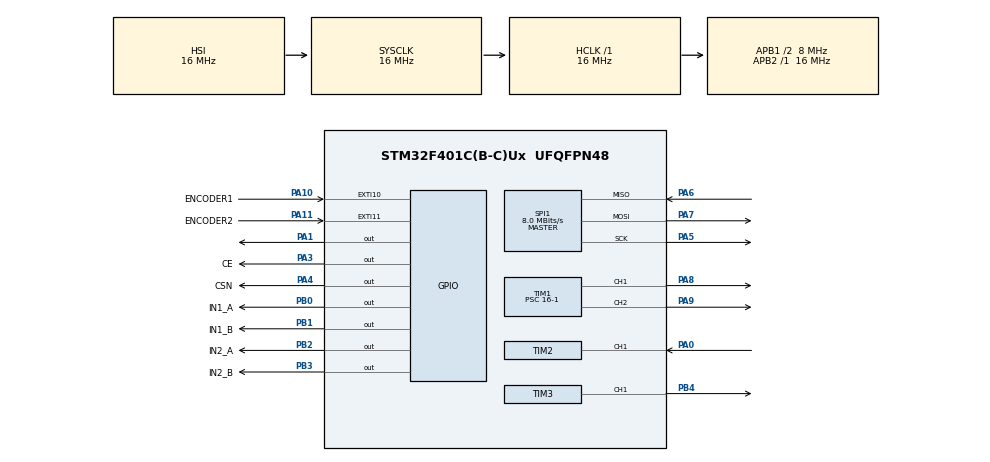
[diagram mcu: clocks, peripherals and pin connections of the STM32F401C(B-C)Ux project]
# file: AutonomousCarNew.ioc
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Mcu.Family=STM32F4
Mcu.Name=STM32F401C(B-C)Ux
Mcu.Package=UFQFPN48
NVIC.EXTI15_10_IRQn=true\:0\:0\:false\:false\:true\:true\:true\:true
NVIC.PriorityGroup=NVIC_PRIORITYGROUP_4
NVIC.TIM2_IRQn=true\:0\:0\:false\:false\:true\:true\:true\:true
PA0-WKUP.Signal=S_TIM2_CH1_ETR
PA1.Signal=GPIO_Output
PA10.GPIO_Label=ENCODER1
PA10.GPIO_PuPd=GPIO_PULLUP
PA10.Signal=GPXTI10
PA11.GPIO_Label=ENCODER2
PA11.GPIO_PuPd=GPIO_PULLUP
PA11.Signal=GPXTI11
PA13.Mode=Serial_Wire
PA13.Signal=SYS_JTMS-SWDIO
PA14.Mode=Serial_Wire
PA14.Signal=SYS_JTCK-SWCLK
PA3.GPIO_Label=CE
PA3.Signal=GPIO_Output
PA4.GPIO_Label=CSN
PA4.Signal=GPIO_Output
PA5.Mode=Full_Duplex_Master
PA5.Signal=SPI1_SCK
PA6.Mode=Full_Duplex_Master
PA6.Signal=SPI1_MISO
PA7.Mode=Full_Duplex_Master
PA7.Signal=SPI1_MOSI
PA8.Signal=S_TIM1_CH1
PA9.Signal=S_TIM1_CH2
PB0.GPIO_Label=IN1_A
PB0.Signal=GPIO_Output
PB1.GPIO_Label=IN1_B
PB1.Signal=GPIO_Output
PB2.GPIO_Label=IN2_A
PB2.Signal=GPIO_Output
PB3.GPIO_Label=IN2_B
PB3.Signal=GPIO_Output
PB4.Signal=S_TIM3_CH1
PH0\ -\ OSC_IN.Mode=HSE-External-Oscillator
PH0\ -\ OSC_IN.Signal=RCC_OSC_IN
PH1\ -\ OSC_OUT.Mode=HSE-External-Oscillator
PH1\ -\ OSC_OUT.Signal=RCC_OSC_OUT
ProjectManager.HeapSize=0x200
ProjectManager.StackSize=0x400
ProjectManager.TargetToolchain=MDK-ARM V5.32
RCC.48MHZClocksFreq_Value=42000000
RCC.AHBFreq_Value=16000000
RCC.APB1CLKDivider=RCC_HCLK_DIV2
RCC.APB1Freq_Value=8000000
RCC.APB1TimFreq_Value=16000000
RCC.APB2Freq_Value=16000000
RCC.APB2TimFreq_Value=16000000
RCC.CortexFreq_Value=16000000
RCC.HCLKFreq_Value=16000000
RCC.HSE_VALUE=25000000
RCC.HSI_VALUE=16000000
RCC.LSE_VALUE=32768
RCC.PLLM=8
RCC.PLLN=84
RCC.SYSCLKFreq_VALUE=16000000
RCC.VCOOutputFreq_Value=168000000
SH.S_TIM1_CH1.0=TIM1_CH1,PWM Generation1 CH1
SH.S_TIM1_CH2.0=TIM1_CH2,PWM Generation2 CH2
SH.S_TIM2_CH1_ETR.0=TIM2_CH1,Input_Capture1_from_TI1
SH.S_TIM3_CH1.0=TIM3_CH1,PWM Generation1 CH1
SPI1.BaudRatePrescaler=SPI_BAUDRATEPRESCALER_2
SPI1.CalculateBaudRate=8.0 MBits/s
SPI1.Direction=SPI_DIRECTION_2LINES
SPI1.Mode=SPI_MODE_MASTER
SPI1.VirtualType=VM_MASTER
TIM1.Channel-PWM\ Generation1\ CH1=TIM_CHANNEL_1
TIM1.Channel-PWM\ Generation2\ CH2=TIM_CHANNEL_2
TIM1.Period=2000
TIM1.Prescaler=16-1
TIM1.Pulse-PWM\ Generation1\ CH1=500
TIM1.Pulse-PWM\ Generation2\ CH2=500
TIM2.Channel-Input_Capture1_from_TI1=TIM_CHANNEL_1
TIM2.Period=0xffffffff
TIM2.Prescaler=16-1
TIM3.Channel-PWM\ Generation1\ CH1=TIM_CHANNEL_1
TIM3.Period=20000
TIM3.Prescaler=16-1
TIM3.Pulse-PWM\ Generation1\ CH1=2000
VP_TIM1_VS_ClockSourceINT.Mode=Internal
VP_TIM2_VS_ClockSourceINT.Mode=Internal
VP_TIM3_VS_ClockSourceINT.Mode=Internal
board=custom

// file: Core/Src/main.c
/* USER CODE BEGIN Header */
/**
  ******************************************************************************
  * @file           : main.c
  * @brief          : Main program body
  ******************************************************************************
  * @attention
  *
  * Copyright (c) 2023 STMicroelectronics.
  * All rights reserved.
  *
  * This software is licensed under terms that can be found in the LICENSE file
  * in the root directory of this software component.
  * If no LICENSE file comes with this software, it is provided AS-IS.
  *
  ******************************************************************************
  */
/* USER CODE END Header */
#include "main.h"

/* USER CODE BEGIN Includes */
#include "NRF24L01.h"
#include "HC_SR04.h"
/* USER CODE END Includes */

/* USER CODE BEGIN PD */
#define MAX_LENGTH_DATA 32
/* USER CODE END PD */

SPI_HandleTypeDef hspi1;

TIM_HandleTypeDef htim1;
TIM_HandleTypeDef htim2;
TIM_HandleTypeDef htim3;

/* USER CODE BEGIN PV */
extern uint8_t Distance;

uint8_t LimitDistance = 20, ReadingSensorAvailable = 1; // 5cm

uint32_t Count1 = 0, Count2 = 0;

uint16_t value;

uint8_t RX_Address[] = {0xEE, 0xDD, 0xCC, 0xBB, 0xAA};

uint8_t RX_Data[MAX_LENGTH_DATA];

typedef struct ReceivedValue
{
	char command1;
	char command2;
	uint16_t data;
} RECEIVED_VALUE;

typedef struct Direction
{
	uint8_t left;
	uint8_t right;
	uint8_t up;
	uint8_t back;
} DIRECTION;

RECEIVED_VALUE DataPackage;

DIRECTION DirectionValue;

void (*ModeFunction) ();

// =============================== FOR PID VARIABLE =================================
//double T, Pulse, Speed, ConstitutionSpeed, E, E1, E2, Alpha, Beta, Gamma, Kp, Kd, Ki, Output, LastOutPut;
double T;

typedef struct PIDType
{
	double Pulse, Speed, ConstitutionSpeed, E, E1, E2, Alpha, Beta, Gamma, Kp, Kd, Ki, Output, LastOutPut;
} PID_TYPE;

PID_TYPE Motor1;
PID_TYPE Motor2;

/* USER CODE END PV */

void SystemClock_Config(void);
static void MX_GPIO_Init(void);
static void MX_SPI1_Init(void);
static void MX_TIM1_Init(void);
static void MX_TIM2_Init(void);
static void MX_TIM3_Init(void);

/* USER CODE BEGIN 0 */
// =========================== FOR PID ALGORITHM =================================

void SetUpPID(PID_TYPE *motor, double cSpeed)
{
	motor->ConstitutionSpeed = cSpeed; // constitution speed in RPM
	//Speed = 0;
	motor->E = motor->E1 = motor->E2 = 0;
	//motor->Output  0;
	motor->LastOutPut = 0;
	T = 0.01;
	motor->Kp = 5, motor->Kd = 0.01, motor->Ki = 0.03;
}

double PID(PID_TYPE *motor, uint32_t *pulse, double T)
{
	motor->Speed = ((double)(*pulse)/20)*(1/T)*60;
	*pulse = 0;
	motor->E = motor->ConstitutionSpeed - motor->Speed;
	motor->Alpha = 2*T*motor->Kp + motor->Ki*T*T + 2*motor->Kd;
	motor->Beta = T*T*motor->Ki - 4*motor->Kd - 2*T*motor->Kp;
	motor->Gamma = 2*motor->Kd;
	motor->Output = (motor->Alpha*motor->E + motor->Beta*motor->E1 + motor->Gamma*motor->E2 + 2*T*motor->LastOutPut)/(2*T);
	motor->LastOutPut = motor->Output;
	motor->E2 = motor->E1;
	motor->E1 = motor->E;
	if (motor->Output > 2000) motor->Output = 2000;
	if (motor->Output < 0) motor->Output = 0;

	return motor->Output;
}

// =========================== FOR ENCODER =================================
void HAL_GPIO_EXTI_Callback(uint16_t GPIO_Pin)
{
	if (GPIO_Pin == ENCODER1_Pin)
	{
		Count1++;
	}
	else if (GPIO_Pin == ENCODER2_Pin)
	{
		Count2++;
	}
}
// =========================== FOR SERVO MOTOR

void RotateAngle(uint16_t angleValue)
{
	uint16_t pwmValue = angleValue * ((2500 - 500)/ 180 - 0) + 500;
	__HAL_TIM_SET_COMPARE(&htim3, TIM_CHANNEL_1, pwmValue);
}

// =========================== FOR MOTOR =================================
void MoveUp(double speed, uint8_t isPID)
{
	HAL_GPIO_WritePin(GPIOB, IN1_A_Pin, GPIO_PIN_RESET);
	HAL_GPIO_WritePin(GPIOB, IN1_B_Pin, GPIO_PIN_SET);
	HAL_GPIO_WritePin(GPIOB, IN2_A_Pin, GPIO_PIN_SET);
	HAL_GPIO_WritePin(GPIOB, IN2_B_Pin, GPIO_PIN_RESET);

	HAL_TIM_PWM_Start(&htim1, TIM_CHANNEL_1);
	HAL_TIM_PWM_Start(&htim1, TIM_CHANNEL_2);

	if (isPID)
	{
		SetUpPID(&Motor1,600);
		SetUpPID(&Motor2,600);
		for (int i = 0; i < 10; i++)
		{
			speed = PID(&Motor1,&Count1, 0.01);
			__HAL_TIM_SET_COMPARE(&htim1, TIM_CHANNEL_1, speed);
			speed = PID(&Motor2,&Count2, 0.01);
			__HAL_TIM_SET_COMPARE(&htim1, TIM_CHANNEL_2, speed);
			HAL_Delay(10);
		}
	}
	else
	{
		__HAL_TIM_SET_COMPARE(&htim1, TIM_CHANNEL_1, speed);
		__HAL_TIM_SET_COMPARE(&htim1, TIM_CHANNEL_2, speed);
		HAL_Delay(80);
	}
	HAL_TIM_PWM_Stop(&htim1, TIM_CHANNEL_1);
	HAL_TIM_PWM_Stop(&htim1, TIM_CHANNEL_2);
}

void MoveBack(uint16_t speed)
{
	HAL_GPIO_WritePin(GPIOB, IN1_A_Pin, GPIO_PIN_SET);
	HAL_GPIO_WritePin(GPIOB, IN1_B_Pin, GPIO_PIN_RESET);
	HAL_GPIO_WritePin(GPIOB, IN2_A_Pin, GPIO_PIN_RESET);
	HAL_GPIO_WritePin(GPIOB, IN2_B_Pin, GPIO_PIN_SET);

	__HAL_TIM_SET_COMPARE(&htim1, TIM_CHANNEL_1, speed);
	__HAL_TIM_SET_COMPARE(&htim1, TIM_CHANNEL_2, speed);
	HAL_TIM_PWM_Start(&htim1, TIM_CHANNEL_1);
	HAL_TIM_PWM_Start(&htim1, TIM_CHANNEL_2);
	HAL_Delay(80);
	HAL_TIM_PWM_Stop(&htim1, TIM_CHANNEL_1);
	HAL_TIM_PWM_Stop(&htim1, TIM_CHANNEL_2);
}

void TurnLeft(uint16_t speed)
{
	HAL_GPIO_WritePin(GPIOB, IN1_A_Pin, GPIO_PIN_RESET);
	HAL_GPIO_WritePin(GPIOB, IN1_B_Pin, GPIO_PIN_SET);
	HAL_GPIO_WritePin(GPIOB, IN2_A_Pin, GPIO_PIN_RESET);
	HAL_GPIO_WritePin(GPIOB, IN2_B_Pin, GPIO_PIN_SET);

	__HAL_TIM_SET_COMPARE(&htim1, TIM_CHANNEL_1, speed);
	__HAL_TIM_SET_COMPARE(&htim1, TIM_CHANNEL_2, speed);
	HAL_TIM_PWM_Start(&htim1, TIM_CHANNEL_1);
	HAL_TIM_PWM_Start(&htim1, TIM_CHANNEL_2);
	HAL_Delay(80);
	HAL_TIM_PWM_Stop(&htim1, TIM_CHANNEL_1);
	HAL_TIM_PWM_Stop(&htim1, TIM_CHANNEL_2);
}

void TurnRight(uint16_t speed)
{
	HAL_GPIO_WritePin(GPIOB, IN1_A_Pin, GPIO_PIN_SET);
	HAL_GPIO_WritePin(GPIOB, IN1_B_Pin, GPIO_PIN_RESET);
	HAL_GPIO_WritePin(GPIOB, IN2_A_Pin, GPIO_PIN_SET);
	HAL_GPIO_WritePin(GPIOB, IN2_B_Pin, GPIO_PIN_RESET);

	__HAL_TIM_SET_COMPARE(&htim1, TIM_CHANNEL_1, speed);
	__HAL_TIM_SET_COMPARE(&htim1, TIM_CHANNEL_2, speed);
	HAL_TIM_PWM_Start(&htim1, TIM_CHANNEL_1);
	HAL_TIM_PWM_Start(&htim1, TIM_CHANNEL_2);
	HAL_Delay(80);
	HAL_TIM_PWM_Stop(&htim1, TIM_CHANNEL_1);
	HAL_TIM_PWM_Stop(&htim1, TIM_CHANNEL_2);
}

void StopMove()
{
	HAL_GPIO_WritePin(GPIOB, IN1_A_Pin, GPIO_PIN_RESET);
	HAL_GPIO_WritePin(GPIOB, IN1_B_Pin, GPIO_PIN_RESET);
	HAL_GPIO_WritePin(GPIOB, IN2_A_Pin, GPIO_PIN_RESET);
	HAL_GPIO_WritePin(GPIOB, IN2_B_Pin, GPIO_PIN_RESET);
	HAL_TIM_PWM_Stop(&htim1, TIM_CHANNEL_1);
	HAL_TIM_PWM_Stop(&htim1, TIM_CHANNEL_2);
	HAL_Delay(80);
}

// =========================== FOR HANDLE RECEIVED VALUES =================================
void ClearDataPackage()
{
	DataPackage.command1 = 0;
	DataPackage.command2 = 0;
	DataPackage.data = 0;
}

void ResetDirection()
{
	DirectionValue.back = 0;
	DirectionValue.left = 0;
	DirectionValue.right = 0;
	DirectionValue.up = 0;
}

uint16_t MappingValue(uint16_t value)
{
	return value * ((float)(2000 - 500) / (float)(2048)) + 500;
}

uint16_t ConvertStringToIntData()
{
	value = 0;
	for (uint8_t i = 2; i < 6; i++)
	{
		value = value*10 + (RX_Data[i] - 0x30);
	}
	return value;
}

void Mode0()
{
	switch (DataPackage.command1)
	{
		case 'L':
		{
			TurnLeft(DataPackage.data);
			ClearDataPackage();
			break;
		}
		case 'R':
		{
			TurnRight(DataPackage.data);
			ClearDataPackage();
			break;
		}
		case 'U':
		{
			MoveUp(DataPackage.data, 0);
			ClearDataPackage();
			break;
		}
		case 'B':
		{
			MoveBack(DataPackage.data);
			ClearDataPackage();
			break;
		}
		default:
		{
			break;
		}
	}
}

void Mode1()
{
	if (ReadingSensorAvailable)
	{
		HCSR04_Read();
		if (Distance < LimitDistance)
		{
			HAL_GPIO_WritePin(GPIOC, GPIO_PIN_13, GPIO_PIN_RESET);
			ReadingSensorAvailable = 0;
			StopMove();
			RotateAngle(15);
			HCSR04_Read();
			HAL_Delay(200);
			uint8_t valueLeft = Distance;
			RotateAngle(170);
			HCSR04_Read();
			HAL_Delay(200);
			uint8_t valueRight = Distance;
			RotateAngle(80);

			if (valueLeft < 20 && valueRight < 20)
			{
				DirectionValue.back = 5;
			}
			if (valueLeft > valueRight)
			{
				DirectionValue.left = 12;
			}
			else
			{
				DirectionValue.right = 12;
			}
			DirectionValue.back += 5;
		}
		else
		{
			ResetDirection();
		}
	}
	if (DirectionValue.back > 0)
	{
		MoveBack(1000);
		DirectionValue.back--;
		return;
	}
	else if (DirectionValue.left > 0)
	{
		TurnLeft(1500);
		DirectionValue.left--;
		return;
	}
	else if (DirectionValue.right > 0)
	{
		TurnRight(1500);
		DirectionValue.right--;
		return;
	}
	HAL_GPIO_WritePin(GPIOC, GPIO_PIN_13, GPIO_PIN_SET);
	ReadingSensorAvailable = 1;
	MoveUp(500, 1); // 500 rpm
}

void ProcessReceivedValue()
{
	if (RX_Data[0] == 'M')
	{
		if (RX_Data[1] == '0')
		{
			HAL_GPIO_WritePin(GPIOC, GPIO_PIN_13, GPIO_PIN_SET);
			ModeFunction = Mode0;
		}
		else if (RX_Data[1] == '1')
		{
			ModeFunction = Mode1;
		}
	}
	else
	{
		if (RX_Data[0] == 'L' || RX_Data[0] == 'B')
		{
			DataPackage.command1 = RX_Data[0];
			DataPackage.data = MappingValue(2048 - ConvertStringToIntData());
		}
		else if (RX_Data[0] == 'R' || RX_Data[0] == 'U')
		{
			DataPackage.command1 = RX_Data[0];
			DataPackage.data = MappingValue(ConvertStringToIntData() - 2048);
		}
	}
}

// =========================== FOR MAIN PROCESS FUNCTION =================================

void MainLoop()
{
	if (isDataAvailable(1) == 1)
	{
		NRF24_Receive(RX_Data);
		ProcessReceivedValue();
	}
	ModeFunction();
}

/* USER CODE END 0 */

int main(void)
{

  /* MCU Configuration--------------------------------------------------------*/

  /* Reset of all peripherals, Initializes the Flash interface and the Systick. */
  HAL_Init();

  /* Configure the system clock */
  SystemClock_Config();

  /* Initialize all configured peripherals */
  MX_GPIO_Init();
  MX_SPI1_Init();
  MX_TIM1_Init();
  MX_TIM2_Init();
  MX_TIM3_Init();
  /* USER CODE BEGIN 2 */
	NRF24_Init();
	NRF24_RxMode(RX_Address, 10);

	HAL_TIM_IC_Start_IT(&htim2, TIM_CHANNEL_1);
	HAL_TIM_PWM_Start(&htim3, TIM_CHANNEL_1);
	ModeFunction = Mode0;
	RotateAngle(80);

	/* USER CODE END 2 */

  /* Infinite loop */
  /* USER CODE BEGIN WHILE */
  while (1)
  {
		MainLoop();
    /* USER CODE END WHILE */
  }
}

void SystemClock_Config(void)
{
  RCC_OscInitTypeDef RCC_OscInitStruct = {0};
  RCC_ClkInitTypeDef RCC_ClkInitStruct = {0};

  /** Configure the main internal regulator output voltage
  */
  __HAL_RCC_PWR_CLK_ENABLE();
  __HAL_PWR_VOLTAGESCALING_CONFIG(PWR_REGULATOR_VOLTAGE_SCALE2);

  /** Initializes the RCC Oscillators according to the specified parameters
  * in the RCC_OscInitTypeDef structure.
  */
  RCC_OscInitStruct.OscillatorType = RCC_OSCILLATORTYPE_HSI;
  RCC_OscInitStruct.HSIState = RCC_HSI_ON;
  RCC_OscInitStruct.HSICalibrationValue = RCC_HSICALIBRATION_DEFAULT;
  RCC_OscInitStruct.PLL.PLLState = RCC_PLL_NONE;
  if (HAL_RCC_OscConfig(&RCC_OscInitStruct) != HAL_OK)
  {
    Error_Handler();
  }

  /** Initializes the CPU, AHB and APB buses clocks
  */
  RCC_ClkInitStruct.ClockType = RCC_CLOCKTYPE_HCLK|RCC_CLOCKTYPE_SYSCLK
                              |RCC_CLOCKTYPE_PCLK1|RCC_CLOCKTYPE_PCLK2;
  RCC_ClkInitStruct.SYSCLKSource = RCC_SYSCLKSOURCE_HSI;
  RCC_ClkInitStruct.AHBCLKDivider = RCC_SYSCLK_DIV1;
  RCC_ClkInitStruct.APB1CLKDivider = RCC_HCLK_DIV2;
  RCC_ClkInitStruct.APB2CLKDivider = RCC_HCLK_DIV1;

  if (HAL_RCC_ClockConfig(&RCC_ClkInitStruct, FLASH_LATENCY_0) != HAL_OK)
  {
    Error_Handler();
  }
}

static void MX_SPI1_Init(void)
{

  /* SPI1 parameter configuration*/
  hspi1.Instance = SPI1;
  hspi1.Init.Mode = SPI_MODE_MASTER;
  hspi1.Init.Direction = SPI_DIRECTION_2LINES;
  hspi1.Init.DataSize = SPI_DATASIZE_8BIT;
  hspi1.Init.CLKPolarity = SPI_POLARITY_LOW;
  hspi1.Init.CLKPhase = SPI_PHASE_1EDGE;
  hspi1.Init.NSS = SPI_NSS_SOFT;
  hspi1.Init.BaudRatePrescaler = SPI_BAUDRATEPRESCALER_2;
  hspi1.Init.FirstBit = SPI_FIRSTBIT_MSB;
  hspi1.Init.TIMode = SPI_TIMODE_DISABLE;
  hspi1.Init.CRCCalculation = SPI_CRCCALCULATION_DISABLE;
  hspi1.Init.CRCPolynomial = 10;
  if (HAL_SPI_Init(&hspi1) != HAL_OK)
  {
    Error_Handler();
  }

}

static void MX_TIM1_Init(void)
{

  TIM_ClockConfigTypeDef sClockSourceConfig = {0};
  TIM_MasterConfigTypeDef sMasterConfig = {0};
  TIM_OC_InitTypeDef sConfigOC = {0};
  TIM_BreakDeadTimeConfigTypeDef sBreakDeadTimeConfig = {0};

  htim1.Instance = TIM1;
  htim1.Init.Prescaler = 16-1;
  htim1.Init.CounterMode = TIM_COUNTERMODE_UP;
  htim1.Init.Period = 2000;
  htim1.Init.ClockDivision = TIM_CLOCKDIVISION_DIV1;
  htim1.Init.RepetitionCounter = 0;
  htim1.Init.AutoReloadPreload = TIM_AUTORELOAD_PRELOAD_DISABLE;
  if (HAL_TIM_Base_Init(&htim1) != HAL_OK)
  {
    Error_Handler();
  }
  sClockSourceConfig.ClockSource = TIM_CLOCKSOURCE_INTERNAL;
  if (HAL_TIM_ConfigClockSource(&htim1, &sClockSourceConfig) != HAL_OK)
  {
    Error_Handler();
  }
  if (HAL_TIM_PWM_Init(&htim1) != HAL_OK)
  {
    Error_Handler();
  }
  sMasterConfig.MasterOutputTrigger = TIM_TRGO_RESET;
  sMasterConfig.MasterSlaveMode = TIM_MASTERSLAVEMODE_DISABLE;
  if (HAL_TIMEx_MasterConfigSynchronization(&htim1, &sMasterConfig) != HAL_OK)
  {
    Error_Handler();
  }
  sConfigOC.OCMode = TIM_OCMODE_PWM1;
  sConfigOC.Pulse = 500;
  sConfigOC.OCPolarity = TIM_OCPOLARITY_HIGH;
  sConfigOC.OCNPolarity = TIM_OCNPOLARITY_HIGH;
  sConfigOC.OCFastMode = TIM_OCFAST_DISABLE;
  sConfigOC.OCIdleState = TIM_OCIDLESTATE_RESET;
  sConfigOC.OCNIdleState = TIM_OCNIDLESTATE_RESET;
  if (HAL_TIM_PWM_ConfigChannel(&htim1, &sConfigOC, TIM_CHANNEL_1) != HAL_OK)
  {
    Error_Handler();
  }
  if (HAL_TIM_PWM_ConfigChannel(&htim1, &sConfigOC, TIM_CHANNEL_2) != HAL_OK)
  {
    Error_Handler();
  }
  sBreakDeadTimeConfig.OffStateRunMode = TIM_OSSR_DISABLE;
  sBreakDeadTimeConfig.OffStateIDLEMode = TIM_OSSI_DISABLE;
  sBreakDeadTimeConfig.LockLevel = TIM_LOCKLEVEL_OFF;
  sBreakDeadTimeConfig.DeadTime = 0;
  sBreakDeadTimeConfig.BreakState = TIM_BREAK_DISABLE;
  sBreakDeadTimeConfig.BreakPolarity = TIM_BREAKPOLARITY_HIGH;
  sBreakDeadTimeConfig.AutomaticOutput = TIM_AUTOMATICOUTPUT_DISABLE;
  if (HAL_TIMEx_ConfigBreakDeadTime(&htim1, &sBreakDeadTimeConfig) != HAL_OK)
  {
    Error_Handler();
  }
  HAL_TIM_MspPostInit(&htim1);

}

static void MX_TIM2_Init(void)
{

  TIM_ClockConfigTypeDef sClockSourceConfig = {0};
  TIM_MasterConfigTypeDef sMasterConfig = {0};
  TIM_IC_InitTypeDef sConfigIC = {0};

  htim2.Instance = TIM2;
  htim2.Init.Prescaler = 16-1;
  htim2.Init.CounterMode = TIM_COUNTERMODE_UP;
  htim2.Init.Period = 0xffffffff;
  htim2.Init.ClockDivision = TIM_CLOCKDIVISION_DIV1;
  htim2.Init.AutoReloadPreload = TIM_AUTORELOAD_PRELOAD_DISABLE;
  if (HAL_TIM_Base_Init(&htim2) != HAL_OK)
  {
    Error_Handler();
  }
  sClockSourceConfig.ClockSource = TIM_CLOCKSOURCE_INTERNAL;
  if (HAL_TIM_ConfigClockSource(&htim2, &sClockSourceConfig) != HAL_OK)
  {
    Error_Handler();
  }
  if (HAL_TIM_IC_Init(&htim2) != HAL_OK)
  {
    Error_Handler();
  }
  sMasterConfig.MasterOutputTrigger = TIM_TRGO_RESET;
  sMasterConfig.MasterSlaveMode = TIM_MASTERSLAVEMODE_DISABLE;
  if (HAL_TIMEx_MasterConfigSynchronization(&htim2, &sMasterConfig) != HAL_OK)
  {
    Error_Handler();
  }
  sConfigIC.ICPolarity = TIM_INPUTCHANNELPOLARITY_RISING;
  sConfigIC.ICSelection = TIM_ICSELECTION_DIRECTTI;
  sConfigIC.ICPrescaler = TIM_ICPSC_DIV1;
  sConfigIC.ICFilter = 0;
  if (HAL_TIM_IC_ConfigChannel(&htim2, &sConfigIC, TIM_CHANNEL_1) != HAL_OK)
  {
    Error_Handler();
  }

}

static void MX_TIM3_Init(void)
{

  TIM_ClockConfigTypeDef sClockSourceConfig = {0};
  TIM_MasterConfigTypeDef sMasterConfig = {0};
  TIM_OC_InitTypeDef sConfigOC = {0};

  htim3.Instance = TIM3;
  htim3.Init.Prescaler = 16-1;
  htim3.Init.CounterMode = TIM_COUNTERMODE_UP;
  htim3.Init.Period = 20000;
  htim3.Init.ClockDivision = TIM_CLOCKDIVISION_DIV1;
  htim3.Init.AutoReloadPreload = TIM_AUTORELOAD_PRELOAD_DISABLE;
  if (HAL_TIM_Base_Init(&htim3) != HAL_OK)
  {
    Error_Handler();
  }
  sClockSourceConfig.ClockSource = TIM_CLOCKSOURCE_INTERNAL;
  if (HAL_TIM_ConfigClockSource(&htim3, &sClockSourceConfig) != HAL_OK)
  {
    Error_Handler();
  }
  if (HAL_TIM_PWM_Init(&htim3) != HAL_OK)
  {
    Error_Handler();
  }
  sMasterConfig.MasterOutputTrigger = TIM_TRGO_RESET;
  sMasterConfig.MasterSlaveMode = TIM_MASTERSLAVEMODE_DISABLE;
  if (HAL_TIMEx_MasterConfigSynchronization(&htim3, &sMasterConfig) != HAL_OK)
  {
    Error_Handler();
  }
  sConfigOC.OCMode = TIM_OCMODE_PWM1;
  sConfigOC.Pulse = 2000;
  sConfigOC.OCPolarity = TIM_OCPOLARITY_HIGH;
  sConfigOC.OCFastMode = TIM_OCFAST_DISABLE;
  if (HAL_TIM_PWM_ConfigChannel(&htim3, &sConfigOC, TIM_CHANNEL_1) != HAL_OK)
  {
    Error_Handler();
  }
  HAL_TIM_MspPostInit(&htim3);

}

static void MX_GPIO_Init(void)
{
  GPIO_InitTypeDef GPIO_InitStruct = {0};

  /* GPIO Ports Clock Enable */
  __HAL_RCC_GPIOH_CLK_ENABLE();
  __HAL_RCC_GPIOA_CLK_ENABLE();
  __HAL_RCC_GPIOB_CLK_ENABLE();
	__HAL_RCC_GPIOC_CLK_ENABLE();

  /*Configure GPIO pin Output Level */
  HAL_GPIO_WritePin(GPIOA, GPIO_PIN_1|CE_Pin|CSN_Pin, GPIO_PIN_RESET);

  /*Configure GPIO pin Output Level */
  HAL_GPIO_WritePin(GPIOB, IN1_A_Pin|IN1_B_Pin|IN2_A_Pin|IN2_B_Pin, GPIO_PIN_RESET);

  /*Configure GPIO pins : PA1 CE_Pin CSN_Pin */
  GPIO_InitStruct.Pin = GPIO_PIN_1|CE_Pin|CSN_Pin;
  GPIO_InitStruct.Mode = GPIO_MODE_OUTPUT_PP;
  GPIO_InitStruct.Pull = GPIO_NOPULL;
  GPIO_InitStruct.Speed = GPIO_SPEED_FREQ_LOW;
  HAL_GPIO_Init(GPIOA, &GPIO_InitStruct);

  /*Configure GPIO pins : IN1_A_Pin IN1_B_Pin IN2_A_Pin IN2_B_Pin */
  GPIO_InitStruct.Pin = IN1_A_Pin|IN1_B_Pin|IN2_A_Pin|IN2_B_Pin;
  GPIO_InitStruct.Mode = GPIO_MODE_OUTPUT_PP;
  GPIO_InitStruct.Pull = GPIO_NOPULL;
  GPIO_InitStruct.Speed = GPIO_SPEED_FREQ_LOW;
  HAL_GPIO_Init(GPIOB, &GPIO_InitStruct);

  /*Configure GPIO pins : ENCODER1_Pin ENCODER2_Pin */
  GPIO_InitStruct.Pin = ENCODER1_Pin|ENCODER2_Pin;
  GPIO_InitStruct.Mode = GPIO_MODE_IT_RISING;
  GPIO_InitStruct.Pull = GPIO_PULLUP;
  HAL_GPIO_Init(GPIOA, &GPIO_InitStruct);

	 /*Configure GPIO pins : PC13 */
  GPIO_InitStruct.Pin = GPIO_PIN_13;
  GPIO_InitStruct.Mode = GPIO_MODE_OUTPUT_PP;
  GPIO_InitStruct.Pull = GPIO_NOPULL;
  GPIO_InitStruct.Speed = GPIO_SPEED_FREQ_LOW;
  HAL_GPIO_Init(GPIOC, &GPIO_InitStruct);

  /* EXTI interrupt init*/
  HAL_NVIC_SetPriority(EXTI15_10_IRQn, 0, 0);
  HAL_NVIC_EnableIRQ(EXTI15_10_IRQn);

}

void Error_Handler(void)
{
  __disable_irq();
  while (1)
  {
  }
}
